# ESP32S31_RADIO register map
Vendor: Espressif; Series: ESP32-S31; File version: 3.52
Registers are 32-bit, read-write, no defined reset value unless marked. A register's access mark holds for its fields unless they carry their own. Offsets are from the block's base; [hi:lo] are bit positions; {n}, {i} and the like mark numbered series.

## SHARED_RADIO_INIT_CONTROL — One physical radio word independently reached by Wi-Fi MAC initialization and Bluetooth receive setup. The owner is protocol-neutral because the two consumers update disjoint fields through fresh-read RMW operations; the name records the observed setup context without assigning an undocumented electrical meaning.
Base 0x20104C24
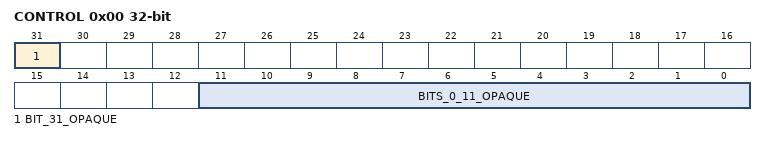
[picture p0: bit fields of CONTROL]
0x00 CONTROL — Project-assigned name. Complete mac_txrx_init replaces the low twelve bits with 0x0F0. Complete bt_bb_rx_set independently clears bit 31. Bits 30:12 remain unnamed.
  [31] BIT_31_OPAQUE — Opaque: meaning not established. Complete bt_bb_rx_set clears this bit through a fresh-read RMW while preserving bits 30:0. Its hardware meaning remains unknown.
  [11:0] BITS_0_11_OPAQUE — Opaque: meaning not established. Complete mac_txrx_init replaces this field with the finite image 0x0F0 while preserving bits 31:12.

## WIFI_MAC_RX_CSI_CONTROL — Multifunction receive/CSI word. Complete mac_last_rxbuf_init sets bit 27; complete hal_init later replaces its low and second bytes through separate RMWs.
Base 0x20104098
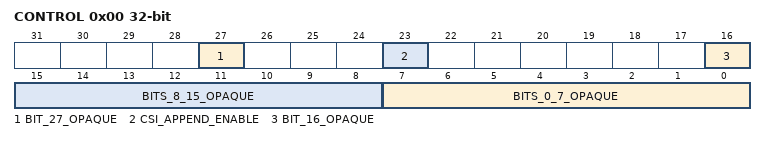
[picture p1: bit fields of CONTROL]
0x00 CONTROL — Project-assigned name. Complete mac_last_rxbuf_init sets bit 27 after publishing all six table entries and both control groups. Complete hal_init later replaces byte zero with one, then byte one with one through a second fresh-read edge.
  [27] BIT_27_OPAQUE — Opaque: meaning not established. Final set edge of mac_last_rxbuf_init; its narrower interaction with CSI is unknown.
  [23] CSI_APPEND_ENABLE — Project-assigned name. hal_mac_set_csi sets or clears bit 23 of the RX/CSI control word.
  [16] BIT_16_OPAQUE — Opaque: meaning not established. Observed source use; the individual hardware meaning is unknown.
  [15:8] BITS_8_15_OPAQUE — Opaque: meaning not established. Complete hal_init replaces bits 15:8 with one through a separate RMW.
    on write: 1=INITIALIZED
  [7:0] BITS_0_7_OPAQUE — Opaque: meaning not established. Complete hal_init replaces bits 7:0 with one.
    on write: 1=INITIALIZED

## WIFI_MAC_LAST_RX_BUFFER — Six three-word last-RX-buffer entries and their shared two-edge enable control, recovered from the complete mac_last_rxbuf_init leaf.
Base 0x20104120
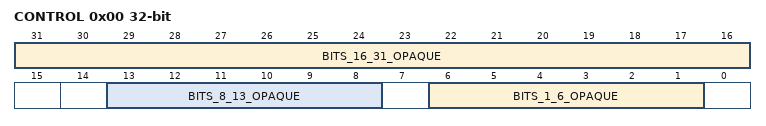
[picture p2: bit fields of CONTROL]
0x00 CONTROL — Project-assigned name. Complete leaf sets bits 13:8 first, then sets bits 6:1 through a second fresh-read RMW.
  [31:16] BITS_16_31_OPAQUE — Opaque: meaning not established. Observed source use; the individual hardware meaning is unknown.
  [13:8] BITS_8_13_OPAQUE — Opaque: meaning not established. All six bits are set by the first control RMW.
  [6:1] BITS_1_6_OPAQUE — Opaque: meaning not established. All six bits are set by the second control RMW.
{0x4+4i} ENTRY_CONTROL{i} (i=0..5) wo — Project-assigned name. First full-word image for each of six entries.
  [31:0] BITS_0_31_OPAQUE — Opaque: meaning not established.
{0x20+4i} ENTRY_PARAMETER_A{i} (i=0..5) wo — Project-assigned name. Second full-word image for each of six entries.
  [31:0] BITS_0_31_OPAQUE — Opaque: meaning not established.
{0x3C+4i} ENTRY_PARAMETER_B{i} (i=0..5) wo — Project-assigned name. Third full-word image for each of six entries.
  [11:0] BITS_0_11_OPAQUE — Opaque: meaning not established. Observed source use; the individual hardware meaning is unknown.

## WIFI_MAC_CORE_ENABLE — Shared MAC enable gate recovered from the complete hal_enable_mac and hal_disable_mac leaves. The four individual disable-bit meanings are not independently known.
Base 0x20104C00
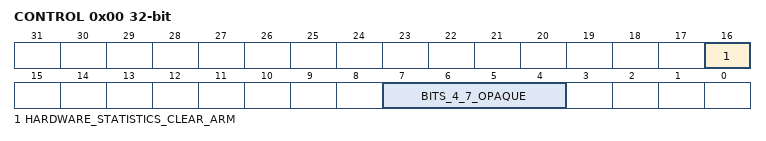
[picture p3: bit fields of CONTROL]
0x00 CONTROL — Project-assigned name. Complete hal_enable_mac clears bits 7:4 in one fresh-read RMW before publishing its interrupt-mask argument; complete hal_disable_mac sets the same four bits. Complete esp_test_clr_hw_statistics independently asserts bit 16 around the separate 0x20104308 bit-zero clear pulse, then clears bit 16.
  [16] HARDWARE_STATISTICS_CLEAR_ARM — Project-assigned name. Set before and cleared after the 0x20104308 clear pulse by complete esp_test_clr_hw_statistics.
  [7:4] BITS_4_7_OPAQUE — Opaque: meaning not established. Zero is the complete hal_enable_mac image and all ones is the complete hal_disable_mac image; individual gate identities remain unknown.
    on write: 0=ENABLED (Clear all four disable gates.); 15=DISABLED (Set all four disable gates.)
